# STM32WBA52 register map
File version: 0.1
CPU: CM33 r0p1, little endian, MPU, FPU, 4 interrupt priority bits
Registers are 32-bit, read-write, reset 0x0 unless marked. A register's access mark holds for its fields unless they carry their own. Offsets are from the block's base; [hi:lo] are bit positions; {n}, {i} and the like mark numbered series.

## CRC — Cyclic redundancy check calculation unit
Base 0x40023000
Same registers: SEC_CRC 0x50023000
0x00 CRC_DR reset 0xFFFFFFFF — CRC data register
  [31:0] DR — Data register bits This register is used to write new data to the CRC calculator. It holds the previous CRC calculation result when it is read. If the data size is less than 32 bits, the least significant bits are used to write/read the correct value.
0x04 CRC_IDR — CRC independent data register
  [31:0] IDR — General-purpose 32-bit data register bits These bits can be used as a temporary storage location for four bytes. This register is not affected by CRC resets generated by the RESET bit in the CRC_CR register
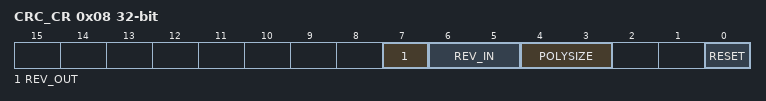
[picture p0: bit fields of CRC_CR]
0x08 CRC_CR — CRC control register
  [7] REV_OUT — Reverse output data This bit controls the reversal of the bit order of the output data.
    0=Bit order not affected; 1=Bit-reversed output format
  [6:5] REV_IN — Reverse input data These bits control the reversal of the bit order of the input data
    0=Bit order not affected; 1=Bit reversal done by byte; 2=Bit reversal done by half-word; 3=Bit reversal done by word
  [4:3] POLYSIZE — Polynomial size These bits control the size of the polynomial.
    0=32 bit polynomial; 1=16 bit polynomial; 2=8 bit polynomial; 3=7 bit polynomial
  [0] RESET — RESET bit This bit is set by software to reset the CRC calculation unit and set the data register to the value stored in the CRC_INIT register. This bit can only be set, it is automatically cleared by hardware
0x10 CRC_INIT reset 0xFFFFFFFF — CRC initial value
  [31:0] CRC_INIT — Programmable initial CRC value This register is used to write the CRC initial value.
0x14 CRC_POL reset 0x4C11DB7 — CRC polynomial
  [31:0] POL — Programmable polynomial This register is used to write the coefficients of the polynomial to be used for CRC calculation. If the polynomial size is less than 32 bits, the least significant bits have to be used to program the correct value.

## GTZC1_MPCBB1 — GTZC1_MPCBB1 address block description
Base 0x40032C00
Same registers: GTZC1_MPCBB2 0x40033000, SEC_GTZC1_MPCBB1 0x50032C00, SEC_GTZC1_MPCBB2 0x50033000
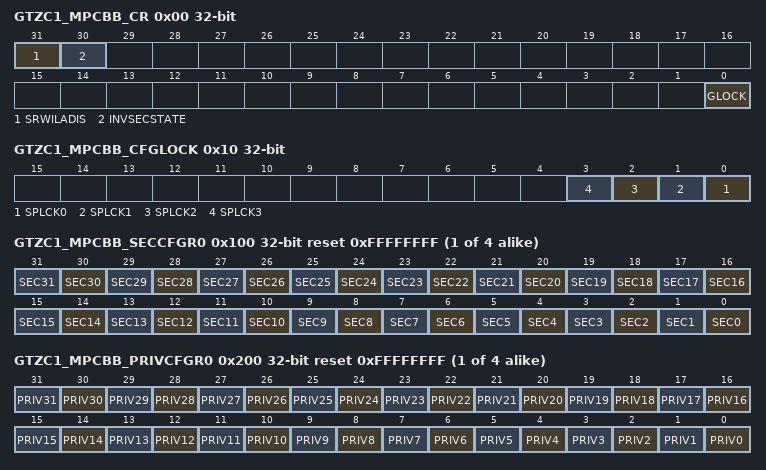
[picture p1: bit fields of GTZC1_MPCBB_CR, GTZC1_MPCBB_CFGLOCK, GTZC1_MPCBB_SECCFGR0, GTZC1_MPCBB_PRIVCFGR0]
0x00 GTZC1_MPCBB_CR — MPCBB control register
  [31] SRWILADIS — secure read/write illegal access disable; This bit disables the detection of an illegal access when a secure read/write transaction access a non-secure blocks of the block-based SRAM (secure fetch on non-secure block is always considered illegal).
    0=enabled, secure read/write acces not allowed on non-secure SRAM block; 1=disabled, secure read/write access allowed on non-secure SRAM block
  [30] INVSECSTATE — SRAM clocks security state; This bit is used to define the internal SRAM clocks control in RCC as secure or not.
    0=SRAM clock is secured if a secure area exists in the MPCBB. It is non secure if there is no secure area.; 1=SRAM clock is non-secure even if a secure area exists in the MPCBB, and secure even if no secure block is set in the MPCBB
  [0] GLOCK — lock the control register of the MPCBB until next reset; This bit is cleared by default and once set, it can not be reset until system reset.
    0=control register not locked; 1=control register locked
0x10 GTZC1_MPCBB_CFGLOCK — GTZC1 SRAMz MPCBB configuration lock register
  [all] fields
    0=GTZC1_MPCBB_SECCFGRn and GTZC1_MPCBB_PRIVCFGRn can be written; 1=Writes to GTZC1_MPCBB_SECCFGRn and GTZC1_MPCBB_PRIVCFGRn are ignored
  [n] SPLCK{n} (n=0..3) — Security/privilege configuration lock super-block; This bit is set by software and can be cleared only by system reset.; note that bit [3:2] are reserved on sales type STM32WBA5xEx for MPCBB1.
{0x100+4i} GTZC1_MPCBB_SECCFGR{i} reset 0xFFFFFFFF (i=0..3) — GTZC1 MPCBB security configuration for super-block {i} register
  [all] fields
    0=Non-secure access only to block y, belonging to super-block n. Secure access is also allowed if the SRWILADIS bit is set in GTZC1_MPCBB_CR.; 1=Secure access only to block y, belonging to super-block n
  [n] SEC{n} (n=0..31) — Security configuration for block y (y = 0 to 31) in super block n Unprivileged write to this bit is ignored if PRIVy bit is set in GTZC1_MPCBB_PRIVCFGRn. Writes are ignored if SPLCKn bit is set in GTZC1_MPCBB_CFGLOCK.
{0x200+4i} GTZC1_MPCBB_PRIVCFGR{i} reset 0xFFFFFFFF (i=0..3) — GTZC1 MPCBB privileged configuration for super-block {i} register
  [all] fields
    0=Privileged and unprivileged access to block y, belonging to super-block n; 1=Only privileged access to block y, belonging to super-block n
  [n] PRIV{n} (n=0..31) — Privileged configuration for block y (y = 0 to 31), belonging to super-block n. Non-secure write to this bit is ignored if SECy bit is set in GTZC1_MPCBB_SECCFGRn. Writes are ignored if SPLCKn bit is set in GTZC1_MPCBB_CFGLOCK.

## GTZC1_MPCBB6 — GTZC1_MPCBB6 address block description
Base 0x40034000
Same registers: SEC_GTZC1_MPCBB6 0x50034000
Registers as GTZC1_MPCBB1, without GTZC1_MPCBB_SECCFGR{n} (n=1..3), GTZC1_MPCBB_PRIVCFGR{n} (n=1..3); these are added or differ:
0x10 GTZC1_MPCBB_CFGLOCK — GTZC1 SRAMz MPCBB configuration lock register
  [0] SPLCK0 — Security/privilege configuration lock super-block; This bit is set by software and can be cleared only by system reset.; note that bit [3:2] are reserved on sales type STM32WBA5xEx for MPCBB1.
    0=GTZC1_MPCBB_SECCFGRn and GTZC1_MPCBB_PRIVCFGRn can be written; 1=Writes to GTZC1_MPCBB_SECCFGRn and GTZC1_MPCBB_PRIVCFGRn are ignored
